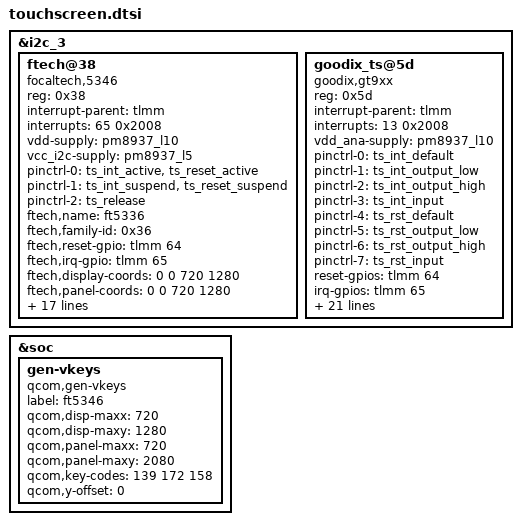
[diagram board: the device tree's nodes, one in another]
&i2c_3 { /* BLSP1 QUP3 */
		status = "ok";
		ftech@38 {
			compatible = "focaltech,5346";
			reg = <0x38>;
			interrupt-parent = <&tlmm>;
			interrupts = <65 0x2008>;
			vdd-supply = <&pm8937_l10>;
			vcc_i2c-supply = <&pm8937_l5>;
			/* pins used by touchscreen */
			pinctrl-names = "pmx_ts_active","pmx_ts_suspend",
				"pmx_ts_release";
			pinctrl-0 = <&ts_int_active &ts_reset_active>;
			pinctrl-1 = <&ts_int_suspend &ts_reset_suspend>;
			pinctrl-2 = <&ts_release>;
			ftech,name = "ft5336";
			ftech,family-id = <0x36>;
			ftech,reset-gpio = <&tlmm 64 0x00>;
			ftech,irq-gpio = <&tlmm 65 0x2008>;
			ftech,display-coords = <0 0 720 1280>;
			ftech,panel-coords = <0 0 720 1280>;
			ftech,virtual-key1 = <139 140 2000>;/*menu*/
			ftech,virtual-key2 = <172 360 2000>;/*home*/
			ftech,virtual-key3 = <158 580 2000>;/*back*/
			ftech,no-force-update;
			ftech,i2c-pull-up;
			ftech,group-id = <1>;
			ftech,hard-reset-delay-ms = <20>;
			ftech,soft-reset-delay-ms = <200>;
			ftech,num-max-touches = <10>;
			ftech,fw-delay-aa-ms = <30>;
			ftech,fw-delay-55-ms = <30>;
			ftech,fw-upgrade-id1 = <0x79>;
			ftech,fw-upgrade-id2 = <0x18>;
			ftech,fw-delay-readid-ms = <10>;
			ftech,fw-delay-era-flsh-ms = <2000>;
			ftech,fw-auto-cal;
			ftech,ignore-id-check;
		};
        goodix_ts@5d{
            compatible = "goodix,gt9xx";
            status = "okay";
            reg = <0x5d>;
            interrupt-parent = <&tlmm>;
            interrupts = <13 0x2008>;
            vdd_ana-supply = <&pm8937_l10>;
            pinctrl-names = "gdix_ts_int_default", "gdix_ts_int_output_low",
                    "gdix_ts_int_output_high", "gdix_ts_int_input",
                    "gdix_ts_rst_default", "gdix_ts_rst_output_low",
                    "gdix_ts_rst_output_high", "gdix_ts_rst_input";
            pinctrl-0 = <&ts_int_default>;
            pinctrl-1 = <&ts_int_output_low>;
            pinctrl-2 = <&ts_int_output_high>;
            pinctrl-3 = <&ts_int_input>;
            pinctrl-4 = <&ts_rst_default>;
            pinctrl-5 = <&ts_rst_output_low>;
            pinctrl-6 = <&ts_rst_output_high>;
            pinctrl-7 = <&ts_rst_input>;
            reset-gpios = <&tlmm 64 0x00>;
            irq-gpios = <&tlmm 65 0x2008>;
            irq-flags = <1>;
            touchscreen-max-id = <10>;
            touchscreen-size-x = <720>;
            touchscreen-size-y = <1280>;
            touchscreen-max-w = <1024>;
            touchscreen-max-p = <1024>;
            touchscreen-key-map = <139>, <172>,<158>;/* KEY_HOMEPAGE=172, KEY_BACK=158，KEY_MENU=139*/
            goodix,type-a-report = <0>;
            goodix,driver-send-cfg = <1>;
            goodix,wakeup-with-reset = <0>;
            goodix,resume-in-workqueue = <1>;
            goodix,int-sync = <1>;
            goodix,swap-x2y = <0>;
            goodix,esd-protect = <1>;
	    goodix,slide-wakeup = <1>;
            goodix,pen-suppress-finger = <0>;
            goodix,auto-update-cfg = <0>;
            goodix,power-off-sleep = <0>;
		goodix,auto-update = <0>;
		goodix,rst-gpio = <&tlmm 64 0x00>;
		goodix,irq-gpio = <&tlmm 65 0x2008>;
        };
};

&soc {
	gen-vkeys {
		compatible = "qcom,gen-vkeys";
		label = "ft5346";
		qcom,disp-maxx = <720>;
		qcom,disp-maxy = <1280>;
		qcom,panel-maxx = <720>;
		qcom,panel-maxy = <2080>;
		qcom,key-codes = <139 172 158>;
		qcom,y-offset = <0>;
	};
};
